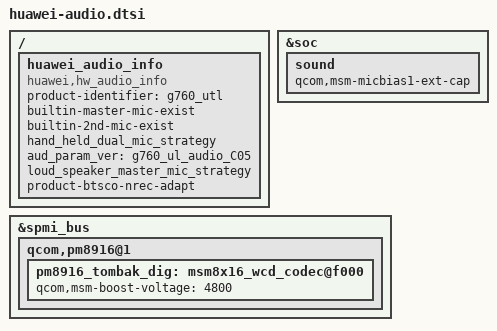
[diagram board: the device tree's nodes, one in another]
/ {
    huawei_audio_info {
        compatible = "huawei,hw_audio_info";
        product-identifier = "g760_utl";
        builtin-master-mic-exist;
        builtin-2nd-mic-exist;
        hand_held_dual_mic_strategy;
        status = "ok";
        aud_param_ver = "g760_ul_audio_C05";
        loud_speaker_master_mic_strategy;
        product-btsco-nrec-adapt;
    };
};
&soc {
    sound {
        qcom,msm-micbias1-ext-cap;
    };
};
&spmi_bus {
        qcom,pm8916@1 {
            pm8916_tombak_dig: msm8x16_wcd_codec@f000{
                qcom,msm-boost-voltage = <4800>;
        };
    };
};
